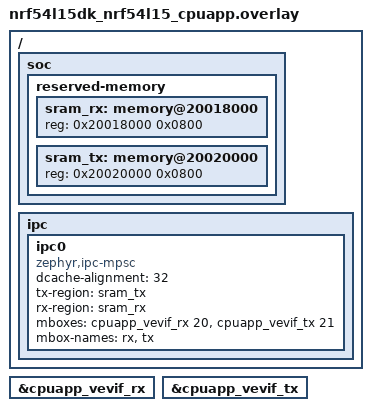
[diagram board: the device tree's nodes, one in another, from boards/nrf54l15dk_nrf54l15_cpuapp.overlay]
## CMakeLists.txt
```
#
# Copyright (c) 2026 Nordic Semiconductor ASA
#
# SPDX-License-Identifier: Apache-2.0
#

cmake_minimum_required(VERSION 3.20.0)

find_package(Zephyr REQUIRED HINTS $ENV{ZEPHYR_BASE})

project(ipc_service_benchmark)

target_include_directories(app PRIVATE ${CMAKE_CURRENT_SOURCE_DIR}/common)

target_sources(app PRIVATE src/main.c)

include(ExternalProject)
```

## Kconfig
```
source "Kconfig.zephyr"

config TEST_MULTI_ENDPOINT
	bool
	depends on !IPC_SERVICE_BACKEND_ICMSG
	default y
```

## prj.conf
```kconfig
CONFIG_ZTEST=y
CONFIG_ZTRESS=y
CONFIG_ZTRESS_MAX_THREADS=4
CONFIG_IPC_SERVICE=y
CONFIG_GPIO=n
CONFIG_TEST_LOGGING_DEFAULTS=n
CONFIG_LOG=y
CONFIG_LOG_BUFFER_SIZE=8192
CONFIG_CPU_LOAD=y
CONFIG_SYSTEM_WORKQUEUE_PRIORITY=-2

CONFIG_ASSERT=n
#CONFIG_IPC_SERVICE_BACKEND_MPSC_IRQ=y
```

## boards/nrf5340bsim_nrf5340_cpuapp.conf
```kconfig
CONFIG_MBOX=y
CONFIG_CPU_LOAD=n
```

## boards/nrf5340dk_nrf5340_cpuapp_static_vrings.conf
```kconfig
CONFIG_SOC_NRF53_CPUNET_ENABLE=y
```

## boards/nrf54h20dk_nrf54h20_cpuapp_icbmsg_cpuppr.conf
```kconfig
CONFIG_MRAM_LATENCY=y
CONFIG_MRAM_LATENCY_AUTO_REQ=y
```

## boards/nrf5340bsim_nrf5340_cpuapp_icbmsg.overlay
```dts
/*
 * SPDX-License-Identifier: Apache-2.0
 */

#include "nrf5340dk_nrf5340_cpuapp_icbmsg.overlay"
```

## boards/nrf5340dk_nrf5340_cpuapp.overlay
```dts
/*
 * Copyright (c) 2022 Nordic Semiconductor ASA
 *
 * SPDX-License-Identifier: Apache-2.0
 */

/ {
	chosen {
		/delete-property/ zephyr,ipc_shm;
	};

	reserved-memory {
		/delete-node/ memory@20070000;

		sram_tx: memory@20070000 {
			reg = <0x20070000 0x0800>;
		};

		sram_rx: memory@20078000 {
			reg = <0x20078000 0x0800>;
		};
	};

	ipc {
		/delete-node/ ipc0;

		ipc0: ipc0 {
			compatible = "zephyr,ipc-mpsc";
			tx-region = <&sram_tx>;
			rx-region = <&sram_rx>;
			mboxes = <&mbox 0>, <&mbox 1>;
			mbox-names = "tx", "rx";
			status = "okay";

			bt_hci_ipc0: bt_hci_ipc0 {
				compatible = "zephyr,bt-hci-ipc";
				status = "okay";
			};
		};
	};
};
```

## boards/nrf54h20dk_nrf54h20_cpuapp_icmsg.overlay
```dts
&ipc0 {
	compatible = "zephyr,ipc-icmsg";
	/delete-property/tx-blocks;
	/delete-property/rx-blocks;
};

&uart136 {
	current-speed = <1000000>;
};
```

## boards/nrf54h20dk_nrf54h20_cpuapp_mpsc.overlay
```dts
&ipc0 {
	compatible = "zephyr,ipc-mpsc";
	/delete-property/tx-blocks;
	/delete-property/rx-blocks;
};

&uart136 {
	current-speed = <1000000>;
};
```

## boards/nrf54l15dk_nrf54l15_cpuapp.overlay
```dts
/*
 * Copyright (c) 2024 Nordic Semiconductor ASA
 *
 * SPDX-License-Identifier: Apache-2.0
 */

/ {
	soc {
		reserved-memory {
			#address-cells = <1>;
			#size-cells = <1>;

			sram_rx: memory@20018000 {
				reg = <0x20018000 0x0800>;
			};

			sram_tx: memory@20020000 {
				reg = <0x20020000 0x0800>;
			};
		};
	};

	ipc {
		ipc0: ipc0 {
			compatible = "zephyr,ipc-mpsc", "zephyr,ipc-icmsg";
			dcache-alignment = <32>;
			tx-region = <&sram_tx>;
			rx-region = <&sram_rx>;
			mboxes = <&cpuapp_vevif_rx 20>, <&cpuapp_vevif_tx 21>;
			mbox-names = "rx", "tx";
			status = "okay";
		};
	};
};

&cpuapp_vevif_rx {
	status = "okay";
};

&cpuapp_vevif_tx {
	status = "okay";
};
```

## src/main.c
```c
/*
 * Copyright (c) 2026 Nordic Semiconductor ASA
 *
 * SPDX-License-Identifier: Apache-2.0
 */

#include "zephyr/ztest_assert.h"
#include <zephyr/kernel.h>
#include <zephyr/device.h>
#include <zephyr/ztest.h>
#include <zephyr/ztress.h>
#include <zephyr/debug/cpu_load.h>
#include <zephyr/random/random.h>
#include <zephyr/ipc/ipc_service.h>
#include <sys/errno.h>
#if defined(CONFIG_SOC_NRF5340_CPUAPP)
#include <nrf53_cpunet_mgmt.h>
#endif
#include <string.h>

#include "common.h"

#include <zephyr/logging/log.h>
LOG_MODULE_REGISTER(host, LOG_LEVEL_INF);

struct stress_ctx {
	uint32_t fail_cnt;
	uint32_t cnt;
	uint32_t rx_cnt;
	uint32_t data_cnt;
};

struct stress_data {
	bool no_copy;
	struct stress_ctx ctx[4];
};

struct test_data {
	uint32_t pkt_cnt;
	uint32_t data_cnt;
	uint32_t busy_cnt;
	uint32_t rpt;
	struct k_sem sem;
	struct ipc_ept ep;
	struct ipc_ept_cfg cfg;
	struct stress_data stress;
};

static const struct device *ipc0;
struct test_data tdata[1];

static bool no_copy_supported(struct ipc_ept *ep)
{
	void *pkt;
	uint32_t len = 16;
	int ret = ipc_service_get_tx_buffer(ep, &pkt, &len, K_NO_WAIT);
	if (ret < 0) {
		return false;
	}

	ipc_service_drop_tx_buffer(ep, pkt);

	return true;
}

static void ep_bound(void *priv)
{
	struct test_data *tdata = priv;

	k_sem_give(&tdata->sem);
	LOG_INF("Ep:%s bounded", tdata->cfg.name);
}

static void send_test_start(const char *test_name)
{
	uint32_t buffer[32];
	struct data_packet *pkt = (struct data_packet *)buffer;
	size_t slen = strlen(test_name);
	size_t pkt_len = slen + 1 + sizeof(struct data_packet);
	int ret;

	pkt->type = TYPE_TEST_START;
	memcpy(pkt->data, test_name, slen);
	pkt->data[slen] = '\0';

	ret = ipc_service_send(&tdata[0].ep, buffer, pkt_len);
	zassert_equal(ret, pkt_len);
}

static void ep_recv_ping_pong(const void *data, size_t len, void *priv)
{
	struct test_data *tdata = priv;
	int ret;

	if (tdata->rpt > 0) {
		ret = ipc_service_send(&tdata->ep, data, len);
		zassert_equal(ret, len);
		tdata->rpt--;
	} else {
		k_sem_give(&tdata->sem);
	}
}

static void ping_pong(const char *test_name, struct test_data *data, size_t len, uint32_t rpt)
{
	uint8_t buffer[32];
	struct data_packet *pkt = (struct data_packet *)buffer;
	uint32_t t;
	int ret;
	uint32_t load;

	send_test_start(test_name);

	zassert_true(len <= sizeof(buffer));

	memset(buffer, 0xaa, len);
	pkt->type = TYPE_RSP;

	data->cfg.cb.received = ep_recv_ping_pong;

	data->rpt = rpt - 1;
	k_sem_init(&data->sem, 0, 1);

	if (IS_ENABLED(CONFIG_CPU_LOAD)) {
		(void)cpu_load_get(true);
	}

	t = k_cycle_get_32();
	ret = ipc_service_send(&data->ep, buffer, len);
	zassert_equal(ret, len, "send failed: %d", ret);

	ret = k_sem_take(&data->sem, K_MSEC(200));
	t = k_cycle_get_32() - t;
	load = IS_ENABLED(CONFIG_CPU_LOAD) ? cpu_load_get(true) : 0;
	t = k_cyc_to_us_floor32(t);
	zassert_equal(ret, 0);

	printk("packet length:%d, avg:%d, cpu_load:%d.%d\n", len, t / rpt, load / 10, load % 10);
}

ZTEST(ipc_service_benchmark, test_turnaround_time_16_bytes)
{
	ping_pong(__func__, &tdata[0], 16, 10);
}

ZTEST(ipc_service_benchmark, test_turnaround_time_32_bytes)
{
	ping_pong(__func__, &tdata[0], 32, 10);
}

static void tx_performance(const char *test_name, struct test_data *data,
			   size_t len, uint32_t timeout_ms, bool nocopy)
{
	uint8_t buffer[128] __aligned(sizeof(uint32_t));
	struct data_packet *pkt = (struct data_packet *)buffer;
	int ret;
	uint32_t load;
	uint32_t end = k_uptime_get_32() + timeout_ms;
	uint8_t pkt_cnt = 0;
	uint32_t speed;

	if (nocopy && !no_copy_supported(&data->ep)) {
		ztest_test_skip();
	}

	send_test_start(test_name);

	data->data_cnt = 0;
	data->busy_cnt = 0;
	zassert_true(len <= sizeof(buffer));

	if (IS_ENABLED(CONFIG_CPU_LOAD)) {
		(void)cpu_load_get(true);
	}

	while (k_uptime_get_32() < end) {
		if (nocopy) {
			ret = ipc_service_get_tx_buffer(&data->ep, (void **)&pkt, &len, K_NO_WAIT);
			if (ret == 0) {
				memset(pkt->data, pkt_cnt, len - sizeof(uint32_t));
				pkt->type = TYPE_NO_RSP;
				pkt->data[0] = (uint8_t)pkt_cnt;
				pkt_cnt++;
				ret = ipc_service_send_nocopy(&data->ep, pkt, len);
				if (ret > 0) {
					data->data_cnt += ret;
				}
			} else if ((ret == -ENOBUFS) || (ret == -ENOMEM)) {
				data->busy_cnt++;
			} else {
				zassert_equal(ret, -EIO);
				ztest_test_skip();
			}
		} else {
			memset(buffer, pkt_cnt, len);
			pkt->type = TYPE_NO_RSP;
			pkt->data[0] = (uint8_t)pkt_cnt;
			pkt_cnt++;

			ret = ipc_service_send(&data->ep, buffer, len);
			if (ret > 0) {
				data->data_cnt += ret;
				LOG_DBG("pkt:%d", pkt_cnt - 1);
			} else if (ret == -ENOMEM) {
				data->busy_cnt++;
			}
		}

#if defined(CONFIG_ARCH_POSIX)
		k_sleep(K_TICKS(1));
#endif
	}

	load = IS_ENABLED(CONFIG_CPU_LOAD) ? cpu_load_get(true) : 0;
	speed = data->data_cnt / timeout_ms;

	printk("packet length:%d, speed:%d kB/s no buffer count: %d cpu_load:%d.%d\n",
			len, speed, data->busy_cnt, load / 10, load % 10);
}

ZTEST(ipc_service_benchmark, test_tx_32_performance)
{
	tx_performance(__func__, &tdata[0], 32, 1000, false);
}

ZTEST(ipc_service_benchmark, test_tx_32_performance_no_copy)
{
	tx_performance(__func__, &tdata[0], 32, 1000, true);
}

ZTEST(ipc_service_benchmark, test_tx_64_performance)
{
	tx_performance(__func__, &tdata[0], 64, 1000, false);
}

ZTEST(ipc_service_benchmark, test_tx_64_performance_no_copy)
{
	tx_performance(__func__, &tdata[0], 64, 1000, true);
}

ZTEST(ipc_service_benchmark, test_tx_128_performance)
{
	tx_performance(__func__, &tdata[0], 128, 1000, false);
}

ZTEST(ipc_service_benchmark, test_tx_128_performance_no_copy)
{
	tx_performance(__func__, &tdata[0], 128, 1000, true);
}

static void ep_recv_stress(const void *data, size_t len, void *priv)
{
	struct test_data *tdata = priv;
	const struct data_packet *pkt = data;
	size_t dlen = len - (sizeof(struct data_packet) + sizeof(uint8_t));
	uint8_t prio = pkt->data[0];
	uint8_t rx_cnt = tdata->stress.ctx[prio].rx_cnt;
	const uint8_t *pkt_data = &pkt->data[1];

	zassert_equal(pkt->type, TYPE_RSP);
	tdata->stress.ctx[prio].rx_cnt++;
	LOG_DBG("rx:%08x", prio | (rx_cnt << 8) | (len << 16));
	for (size_t i = 0; i < dlen; i++) {
		uint8_t exp = rx_cnt + i;

		zassert_equal(pkt_data[i], exp,
				"Unexpected byte at %d, got %02x exp:%02x",
				i, pkt_data[i], exp);
	}
}

static bool ipc_producer(void *user_data, uint32_t cnt, bool last, int prio)
{
	struct test_data *tdata = user_data;
	struct stress_data *sdata = &tdata->stress;
	size_t rpt = 1 + sys_rand32_get() % 4;

	while (rpt) {
		size_t len = 8 + sys_rand32_get() % 32;
		size_t dlen = len - (sizeof(struct data_packet) + sizeof(uint8_t));
		struct data_packet *pkt;
		uint8_t tx_cnt = sdata->ctx[prio].cnt;
		uint32_t buffer[16];
		int ret;

		if (sdata->no_copy) {
			ret = ipc_service_get_tx_buffer(&tdata->ep, (void **)&pkt, &len, K_NO_WAIT);
			if (ret < 0) {
				sdata->ctx[prio].fail_cnt++;
				return true;
			}
		} else {
			pkt = (struct data_packet *)buffer;
		}

		pkt->type = TYPE_RSP;
		pkt->data[0] = prio;
		for (size_t i = 0; i < dlen; i++) {
			pkt->data[i + 1] = tx_cnt + i;
		};

		LOG_DBG("tx:%08x", prio | (tx_cnt << 8) | (len << 16));
		if (sdata->no_copy) {
			ret = ipc_service_send_nocopy(&tdata->ep, pkt, len);
		} else {
			ret = ipc_service_send(&tdata->ep, pkt, len);
		}

		if (ret < 0) {
			sdata->ctx[prio].fail_cnt++;
			return true;
		}

		sdata->ctx[prio].cnt++;
		sdata->ctx[prio].data_cnt += ret;
		rpt--;
	}

	return true;
}

static void test_stress(const char *test_name, bool no_copy)
{
	uint32_t preempt_max = 4000;
	k_timeout_t t = Z_TIMEOUT_TICKS(20);
	uint32_t tstamp;
	uint32_t load;
	uint32_t total = 0;

	if (no_copy && !no_copy_supported(&tdata[0].ep)) {
		ztest_test_skip();
	}

	send_test_start(test_name);

	memset(&tdata[0].stress, 0, sizeof(tdata[0].stress));
	tdata[0].stress.no_copy = no_copy;

	ztress_set_timeout(K_MSEC(2000));

	tdata[0].cfg.cb.received = ep_recv_stress;

	if (IS_ENABLED(CONFIG_CPU_LOAD)) {
		(void)cpu_load_get(true);
	}

	tstamp = k_cycle_get_32();
	ZTRESS_EXECUTE(ZTRESS_THREAD(ipc_producer,  &tdata[0], 0, 0, t),
		       ZTRESS_THREAD(ipc_producer, &tdata[0], 0, preempt_max, t),
		       ZTRESS_THREAD(ipc_producer, &tdata[0], 0, preempt_max, t));

	tstamp = k_cycle_get_32() - tstamp;
	tstamp = k_cyc_to_ms_floor32(tstamp);
	load = IS_ENABLED(CONFIG_CPU_LOAD) ? cpu_load_get(true) : 0;
	for (int i = 0; i < 3; i++) {
		total += tdata[0].stress.ctx[i].data_cnt;
	}

	TC_PRINT("\nTest took %d ms. Speed:%d kB/s, CPU load %d.%d\n",
			tstamp, total / tstamp, load / 10, load % 10);
	for (int i = 0; i < 3; i++) {
		TC_PRINT("\t - Context %d sent %d packets (%d bytes). Fails:%d\n",
			i, tdata[0].stress.ctx[i].cnt, tdata[0].stress.ctx[i].data_cnt,
			tdata[0].stress.ctx[i].fail_cnt);
		total += tdata[0].stress.ctx[i].data_cnt;
	}
}

ZTEST(ipc_service_benchmark, test_stress)
{
	test_stress(__func__, false);
}

ZTEST(ipc_service_benchmark, test_stress_no_copy)
{
	/* Test is failing on static_vrings and icbmsg backends. */
	ztest_test_skip();
	test_stress(__func__, true);
}

static void *setup(void)
{
	int ret;

	TC_PRINT("Testing %s IPC service\n",
			IS_ENABLED(CONFIG_IPC_SERVICE_BACKEND_ICBMSG) ? "icbmsg" :
			IS_ENABLED(CONFIG_IPC_SERVICE_BACKEND_RPMSG) ? "static_vrings" :
			"icmsg");

	ipc0 = DEVICE_DT_GET(DT_NODELABEL(ipc0));
	ret = ipc_service_open_instance(ipc0);
	zassert_ok(ret, "Unexpected error: %d", ret);

	tdata[0].cfg.name = "ep0";
	tdata[0].cfg.cb.bound = ep_bound;
	tdata[0].cfg.priv = &tdata[0];
	/*tdata[0].cfg.prio = 1;*/
	k_sem_init(&tdata[0].sem, 0, 1);

	ret = ipc_service_register_endpoint(ipc0, &tdata[0].ep, &tdata[0].cfg);
	zassert_equal(ret, 0);

	ret = k_sem_take(&tdata[0].sem, K_MSEC(100));
	zassert_equal(ret, 0);

	return NULL;
}

static void after(void *unused)
{
	uint32_t buffer[1];
	struct data_packet *pkt = (struct data_packet *)buffer;
	int ret;

	pkt->type = TYPE_TEST_END;

	/* Wait some time for the remote to process test messages. */
	k_msleep(10);
	ret = ipc_service_send(&tdata[0].ep, buffer, sizeof(buffer));
	zassert_equal(ret, sizeof(buffer));

	k_msleep(50);
}

ZTEST_SUITE(ipc_service_benchmark, NULL, setup, NULL, after, NULL);
```
